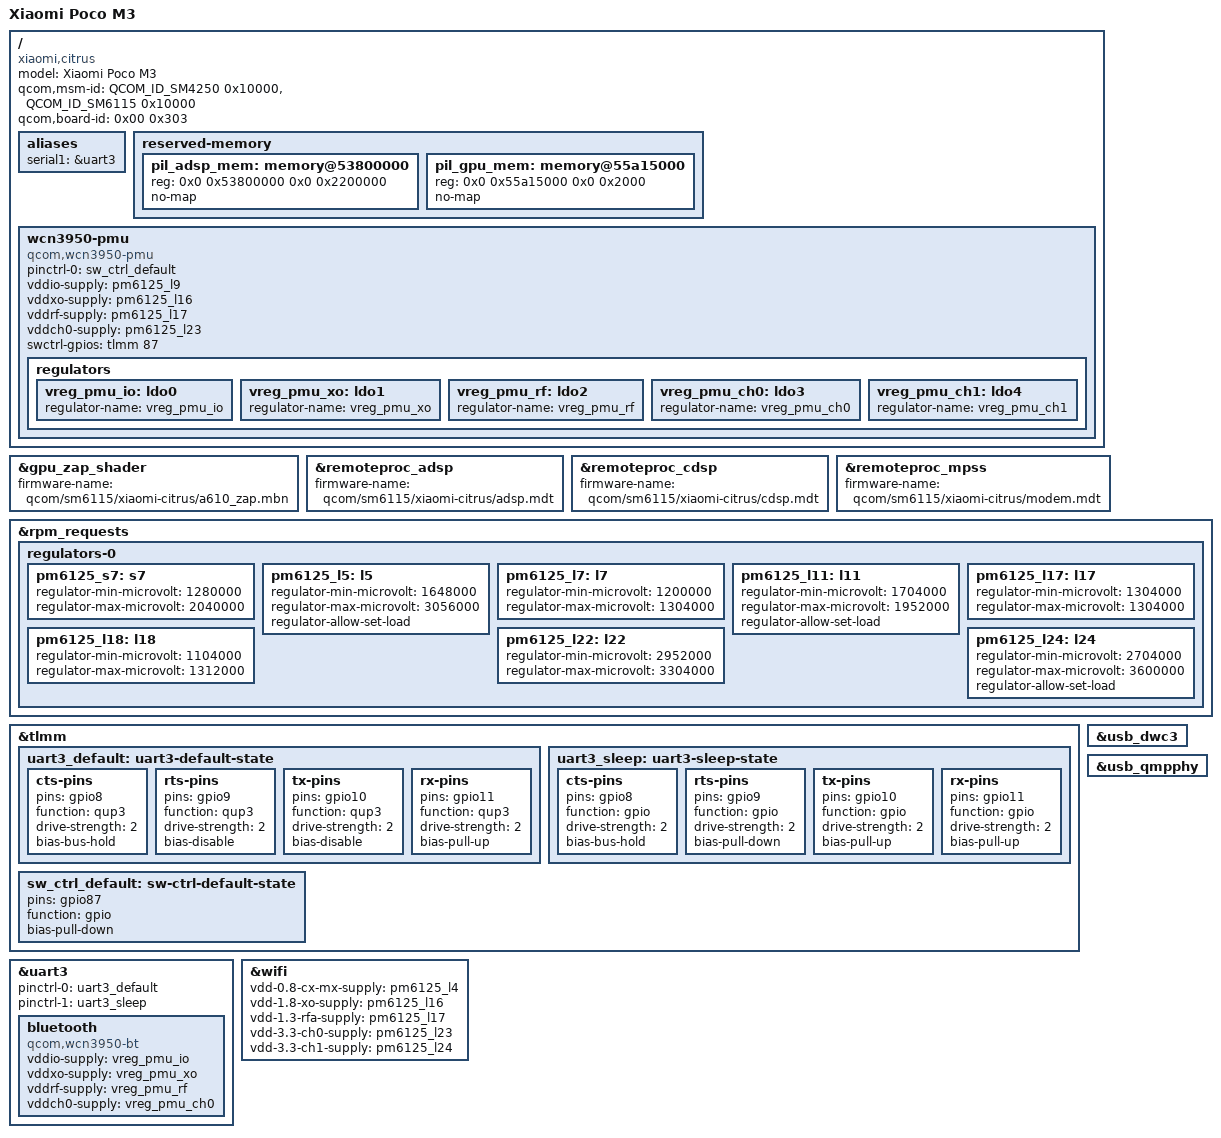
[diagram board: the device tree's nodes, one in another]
// SPDX-License-Identifier: (GPL-2.0+ OR BSD-3-Clause)
/*
 * Copyright (c) 2023 - 2024, Dang Huynh <danct12@riseup.net>
 * Copyright (c) 2026, Amir Hanip <killdeath104@gmail.com>
 */

/dts-v1/;

#include <dt-bindings/arm/qcom,ids.h>
#include "sm6115-xiaomi-lime-common.dtsi"

/delete-node/ &cdsp_sec_mem;

/ {
	model = "Xiaomi Poco M3";
	compatible = "xiaomi,citrus", "qcom,sm6115";

	qcom,msm-id = <QCOM_ID_SM4250 0x10000>, <QCOM_ID_SM6115 0x10000>;
	qcom,board-id = <0x00 0x303>;

	aliases {
		serial1 = &uart3;
	};

	reserved-memory {
		pil_adsp_mem: memory@53800000 {
			reg = <0x0 0x53800000 0x0 0x2200000>;
			no-map;
		};

		pil_gpu_mem: memory@55a15000 {
			reg = <0x0 0x55a15000 0x0 0x2000>;
			no-map;
		};
	};

	wcn3950-pmu {
		compatible = "qcom,wcn3950-pmu";

		pinctrl-0 = <&sw_ctrl_default>;
		pinctrl-names = "default";

		vddio-supply = <&pm6125_l9>;
		vddxo-supply = <&pm6125_l16>;
		vddrf-supply = <&pm6125_l17>;
		vddch0-supply = <&pm6125_l23>;

		swctrl-gpios = <&tlmm 87 GPIO_ACTIVE_HIGH>;

		regulators {
			vreg_pmu_io: ldo0 {
				regulator-name = "vreg_pmu_io";
			};

			vreg_pmu_xo: ldo1 {
				regulator-name = "vreg_pmu_xo";
			};

			vreg_pmu_rf: ldo2 {
				regulator-name = "vreg_pmu_rf";
			};

			vreg_pmu_ch0: ldo3 {
				regulator-name = "vreg_pmu_ch0";
			};

			vreg_pmu_ch1: ldo4 {
				regulator-name = "vreg_pmu_ch1";
			};
		};
	};
};

&gpu_zap_shader {
	firmware-name = "qcom/sm6115/xiaomi-citrus/a610_zap.mbn";
};

&remoteproc_adsp {
	firmware-name = "qcom/sm6115/xiaomi-citrus/adsp.mdt";
};

&remoteproc_cdsp {
	firmware-name = "qcom/sm6115/xiaomi-citrus/cdsp.mdt";
};

&remoteproc_mpss {
	firmware-name = "qcom/sm6115/xiaomi-citrus/modem.mdt";
};

&rpm_requests {
	regulators-0 {
		pm6125_s7: s7 {
			regulator-min-microvolt = <1280000>;
			regulator-max-microvolt = <2040000>;
		};

		pm6125_l5: l5 {
			regulator-min-microvolt = <1648000>;
			regulator-max-microvolt = <3056000>;
			regulator-allow-set-load;
		};

		pm6125_l7: l7 {
			regulator-min-microvolt = <1200000>;
			regulator-max-microvolt = <1304000>;
		};

		pm6125_l11: l11 {
			regulator-min-microvolt = <1704000>;
			regulator-max-microvolt = <1952000>;
			regulator-allow-set-load;
		};

		pm6125_l17: l17 {
			regulator-min-microvolt = <1304000>;
			regulator-max-microvolt = <1304000>;
		};

		pm6125_l18: l18 {
			regulator-min-microvolt = <1104000>;
			regulator-max-microvolt = <1312000>;
		};

		pm6125_l22: l22 {
			regulator-min-microvolt = <2952000>;
			regulator-max-microvolt = <3304000>;
		};

		pm6125_l24: l24 {
			regulator-min-microvolt = <2704000>;
			regulator-max-microvolt = <3600000>;
			regulator-allow-set-load;
		};
	};
};

&tlmm {
	uart3_default: uart3-default-state {
		cts-pins {
			pins = "gpio8";
			function = "qup3";
			drive-strength = <2>;
			bias-bus-hold;
		};

		rts-pins {
			pins = "gpio9";
			function = "qup3";
			drive-strength = <2>;
			bias-disable;
		};

		tx-pins {
			pins = "gpio10";
			function = "qup3";
			drive-strength = <2>;
			bias-disable;
		};

		rx-pins {
			pins = "gpio11";
			function = "qup3";
			drive-strength = <2>;
			bias-pull-up;
		};
	};

	uart3_sleep: uart3-sleep-state {
		cts-pins {
			pins = "gpio8";
			function = "gpio";
			drive-strength = <2>;
			bias-bus-hold;
		};

		rts-pins {
			pins = "gpio9";
			function = "gpio";
			drive-strength = <2>;
			bias-pull-down;
		};

		tx-pins {
			pins = "gpio10";
			function = "gpio";
			drive-strength = <2>;
			bias-pull-up;
		};

		rx-pins {
			pins = "gpio11";
			function = "gpio";
			drive-strength = <2>;
			bias-pull-up;
		};
	};

	sw_ctrl_default: sw-ctrl-default-state {
		pins = "gpio87";
		function = "gpio";
		bias-pull-down;
	};
};

&uart3 {
	pinctrl-0 = <&uart3_default>;
	pinctrl-1 = <&uart3_sleep>;
	pinctrl-names = "default", "sleep";

	status = "okay";

	bluetooth {
		compatible = "qcom,wcn3950-bt";
		vddio-supply = <&vreg_pmu_io>;
		vddxo-supply = <&vreg_pmu_xo>;
		vddrf-supply = <&vreg_pmu_rf>;
		vddch0-supply = <&vreg_pmu_ch0>;
	};
};

&usb_dwc3 {
	status = "okay";
};

&usb_qmpphy {
	/delete-property/ orientation-switch;
};

&wifi {
	vdd-0.8-cx-mx-supply = <&pm6125_l4>;
	vdd-1.8-xo-supply = <&pm6125_l16>;
	vdd-1.3-rfa-supply = <&pm6125_l17>;
	vdd-3.3-ch0-supply = <&pm6125_l23>;
	vdd-3.3-ch1-supply = <&pm6125_l24>;

	status = "okay";
};
